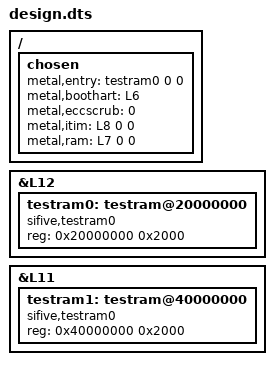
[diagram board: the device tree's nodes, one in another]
/include/ "core.dts"
/ {
	chosen {
		metal,entry = <&testram0 0 0>;
		metal,boothart = <&L6>;
		metal,eccscrub = <0>;
		metal,itim = <&L8 0 0>;
		metal,ram = <&L7 0 0>;
	};
};
&L12 {
	testram0: testram@20000000 {
		compatible = "sifive,testram0";
		reg = <0x20000000 0x2000>;
		reg-names = "mem";
	};
};
&L11 {
	testram1: testram@40000000 {
		compatible = "sifive,testram0";
		reg = <0x40000000 0x2000>;
		reg-names = "mem";
	};
};
